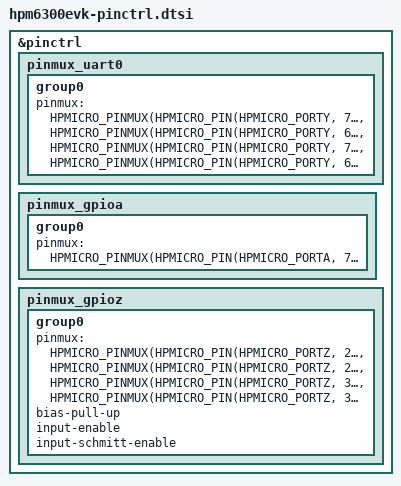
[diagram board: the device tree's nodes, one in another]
/*
 * Copyright 2024 hpmicro
 * SPDX-License-Identifier: Apache-2.0
 */
 
#include "dt-bindings/pinctrl/hpmicro-pinctrl-common.h"

&pinctrl {
	pinmux_uart0: pinmux_uart0 {
		group0 {
			pinmux = <HPMICRO_PINMUX(HPMICRO_PIN(HPMICRO_PORTY, 7), IOC_TYPE_IOC, 0, 2)>,
					 <HPMICRO_PINMUX(HPMICRO_PIN(HPMICRO_PORTY, 6), IOC_TYPE_IOC, 0, 2)>,
					 <HPMICRO_PINMUX(HPMICRO_PIN(HPMICRO_PORTY, 7), IOC_TYPE_PIOC, 0, 3)>,
					 <HPMICRO_PINMUX(HPMICRO_PIN(HPMICRO_PORTY, 6), IOC_TYPE_PIOC, 0, 3)>;
		};
	};
	pinmux_gpioa: pinmux_gpioa {
		group0 {
			pinmux = <HPMICRO_PINMUX(HPMICRO_PIN(HPMICRO_PORTA, 7), IOC_TYPE_IOC, 0, 0)>;
		};
	};

	pinmux_gpioz: pinmux_gpioz {
		group0 {
			pinmux = <HPMICRO_PINMUX(HPMICRO_PIN(HPMICRO_PORTZ, 2), IOC_TYPE_IOC, 0, 0)>,
					 <HPMICRO_PINMUX(HPMICRO_PIN(HPMICRO_PORTZ, 2), IOC_TYPE_BIOC, 0, 3)>,
					 <HPMICRO_PINMUX(HPMICRO_PIN(HPMICRO_PORTZ, 3), IOC_TYPE_IOC, 0, 0)>,
					 <HPMICRO_PINMUX(HPMICRO_PIN(HPMICRO_PORTZ, 3), IOC_TYPE_BIOC, 0, 3)>;
			bias-pull-up;
			input-enable;
			input-schmitt-enable;
		};
	};
};
